# A31G11x_series register map
Vendor: ABOV Semiconductor Co., Ltd.; Series: A31G11x_series; File version: 1.0
CPU: CM0PLUS r0p1, little endian, no MPU, no FPU, VTOR, 2 interrupt priority bits
Registers are 32-bit, read-write, reset 0x0 unless marked. A register's access mark holds for its fields unless they carry their own. Offsets are from the block's base; [hi:lo] are bit positions.

## FMC — FLASH MEMORY CONTROLLER
Base 0x40001B00
0x00 FMC_ADR reset 0x5FFFFF80 — Flash Memory Address Register. Note: The LSB-2bits of the target flash address is always considered to "00b".
  [31:0] ADDR — Flash Memory Address Pointer. This register is reset to 0x5FFFFF80 immediately after one time operation.
0x04 FMC_IDR1 — Flash Memory Identification Register 1
  [31:0] ID0 — Flash Memory Identification 0
0x08 FMC_IDR2 — Flash Memory Identification Register 2. Notes: 1. The FMIDR0/1 registers are automatically cleared to logic 0x00000000 immediately after one time operation except "flash page buffer reset mode". 2. The FMIDR0/1 registers should be written with correct values in turn. 3. If incorrect values are written to the FMIDR0/1 registers, the registers are cleared to logic 0x00000000.
  [31:0] ID1 — Flash Memory Identification 1
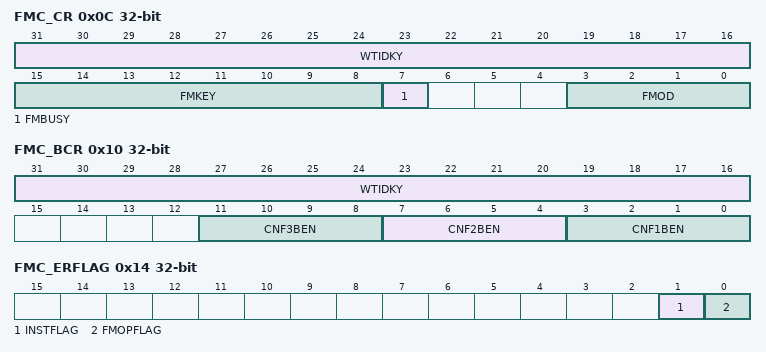
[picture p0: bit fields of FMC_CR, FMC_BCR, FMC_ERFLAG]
0x0C FMC_CR — Flash Memory Control Register. Notes: 1. During a flash memory operation mode, the all interrupts are on disable state regardless of enable bits. 2. The FMKEY[7:0] and FMOD[3:0] bits are automatically cleared to logic "0x00" immediately after one time operation.
  [31:16] WTIDKY wo — Write Identification Key. On writes, write 0x6C93 to these bits, otherwise the write is ignored.
  [15:8] FMKEY — Flash Memory Operation Area Selection bits
  [7] FMBUSY ro — Flash Memory Operation Mode Busy bit
  [3:0] FMOD — Flash Memory Operation Mode Selection bits
0x10 FMC_BCR — Flash Memory Configure Area Bulk Erase Control Register. Note: This register is automatically cleared to logic "0x00" immediately after one time operation.
  [31:16] WTIDKY wo — Write Identification Key. On writes, write 0xC1BE to these bits, otherwise the write is ignored.
  [11:8] CNF3BEN — Configure Option Page 3 Bulk Erase Enable bits.
  [7:4] CNF2BEN — Configure Option Page 2 Bulk Erase Enable bits.
  [3:0] CNF1BEN — Configure Option Page 1 Bulk Erase Enable bits.
0x14 FMC_ERFLAG (reset mask 0x1) — Flash Memory Hard Fault Flag
  [1] INSTFLAG — Don't care
  [0] FMOPFLAG — Error bit of Flash Memory Operation Procedure. This bit is set to logic 1 if there is a wrong procedure for flash memory operation.
0x100 FMC_PAGEBUF wo — Flash Memory Page Buffer Area

## WT — WATCH TIMER
Base 0x40002000
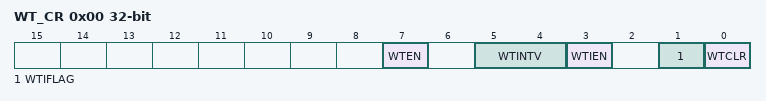
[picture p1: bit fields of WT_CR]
0x00 WT_CR — Watch Timer Control Register
  [7] WTEN — Watch Timer Operation Enable bit
    0=DISABLE_WT (Disable watch timer operation); 1=ENABLE_WT (Enable watch timer operation)
  [5:4] WTINTV — Watch Timer Interval Selection bits.
    0=WT_IF_INTERVAL_7 (fWT/2^7); 1=WT_IF_INTERVAL_13 (fWT/2^13); 2=WT_IF_INTERVAL_14 (fWT/2^14); 3=WT_IF_INTERVAL_14_ (fWT/(2^14x(WTDR value + 1)))
  [3] WTIEN — Watch Timer Interrupt Enable bit
    0=DISABLE_WT_INT (Disable watch timer interrupt); 1=ENABLE_WT_INT (Enable watch timer interrupt)
  [1] WTIFLAG — Watch Timer Interrupt Flag bit
    0=WT_IF_CLR (No request occurred); 1=WT_IF_SET (Request occurred, This bit is cleared to '0' when write '1'.)
  [0] WTCLR — Watch Timer Counter and Divider Clear bit
    0=LET_WT_CNT_BE (No effect); 1=CLEAR_WT_CNT (Clear the counter and divider (Automatically cleared to "0b" after operation))
0x04 WT_DR reset 0xFFF — Watch Timer Data Register
  [11:0] WTDATA — Watch Timer Data bits. The range is 0x001 to 0xFFF.
0x08 WT_CNT ro — Watch Timer Counter Register
  [11:0] CNT — Watch Timer Counter bits.

## T10 — TIMER COUNTER 10/11/12
Base 0x40002100
Same registers: T11 0x40002200, T12 0x40002300
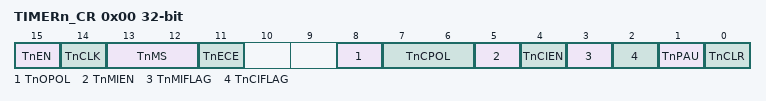
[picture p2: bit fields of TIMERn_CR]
0x00 TIMERn_CR — Timer/Counter n Control Register
  [15] TnEN — Timer n Operation Enable bit
  [14] TnCLK — Timer n Clock Selection bit (Note: This bit should be changed during TnEN bit is "0b".)
  [13:12] TnMS — Timer n Operation Mode Selection bits (Note: These bits should be changed during TnEN bit is "0b".)
  [11] TnECE — Timer n External Clock Edge Selection bit
  [8] TnOPOL — TnOUT Polarity Selection bit
  [7:6] TnCPOL — Timer n Capture Polarity Selection bits
  [5] TnMIEN — Timer n Match Interrupt Enable bit
  [4] TnCIEN — Timer n Capture Interrupt Enable bit
  [3] TnMIFLAG — Timer n Match Interrupt Flag bit
  [2] TnCIFLAG — Timer n Capture Interrupt Flag bit
  [1] TnPAU — Timer n Counter Temporary Pause Control bit
  [0] TnCLR — Timer n Counter and Prescaler Clear bit
0x04 TIMERn_ADR reset 0xFFFF — Timer/Counter n A Data Register
  [15:0] ADATA — Timer/Counter n A Data bits. The range is 0x0000 to 0xFFFF. Note: Do not write "0000H" in the TnADR register when PPG mode.
0x08 TIMERn_BDR reset 0xFFFF — Timer/Counter n B Data Register
  [15:0] BDATA — Timer/Counter n B Data bits. The range is 0x0000 to 0xFFFF.
0x0C TIMERn_CAPDR ro — Timer/Counter n Capture Data Register
  [15:0] CAPD — Timer/Counter n Capture Data bits.
0x10 TIMERn_PREDR reset 0xFFF — Timer/Counter n Prescaler Data Register
  [11:0] PRED — Timer/Counter n Prescaler Data bits.
0x14 TIMERn_CNT ro — Timer/Counter n Counter Register
  [15:0] CNT — Timer/Counter n Counter bits.
